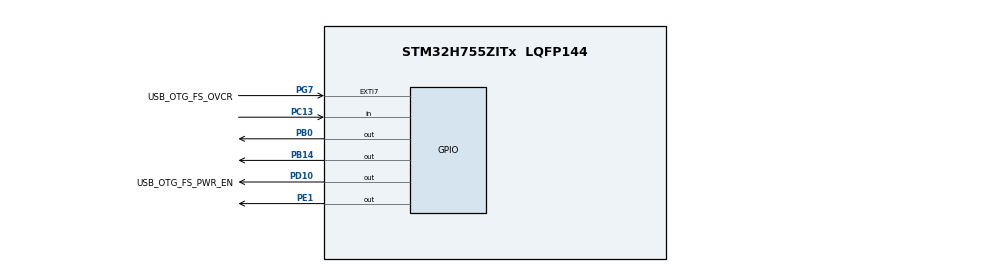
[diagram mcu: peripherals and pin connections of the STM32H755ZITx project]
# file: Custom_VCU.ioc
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CortexM4.IPs=FATFS_M4\:I,FREERTOS_M4\:I,IWDG2\:I,RCC,WWDG2\:I,DMA,BDMA,MDMA,NVIC2\:I,ETH,USART3,DEBUG,PDM2PCM_M4\:I,PWR,RESMGR_UTILITY,SYS_M4\:I,USB_DEVICE_M4\:I,USB_HOST_M4\:I,CORTEX_M4\:I,GPIO,OPENAMP_M4\:I,VREFBUF,NUCLEO-H755ZI-Q,TIM2\:I
CortexM7.IPs=FATFS_M7\:I,FREERTOS_M7\:I,IWDG1\:I,RCC\:I,WWDG1\:I,DMA\:I,BDMA\:I,MDMA\:I,NVIC1\:I,ETH\:I,USART3\:I,USB_OTG_FS\:I,SYS\:I,CORTEX_M7\:I,DEBUG\:I,PDM2PCM_M7\:I,PWR\:I,RESMGR_UTILITY\:I,USB_DEVICE_M7\:I,USB_HOST_M7\:I,GPIO\:I,OPENAMP_M7\:I,VREFBUF\:I,NUCLEO-H755ZI-Q\:I,MEMORYMAP\:I,TIM1\:I
FREERTOS_M4.Tasks01=defaultTask,0,128,StartDefaultTask,Default,NULL,Dynamic,NULL,NULL
FREERTOS_M4.configUSE_NEWLIB_REENTRANT=1
FREERTOS_M7.Tasks01=defaultTask,0,128,StartDefaultTask,Default,NULL,Dynamic,NULL,NULL
FREERTOS_M7.configUSE_NEWLIB_REENTRANT=1
Mcu.Family=STM32H7
Mcu.Name=STM32H755ZITx
Mcu.Package=LQFP144
NUCLEO-H755ZI-Q.BUTTON=1
NUCLEO-H755ZI-Q.Bsp_Common_DEMO=true
NUCLEO-H755ZI-Q.LD1=true
NUCLEO-H755ZI-Q.LD2=true
NUCLEO-H755ZI-Q.LD3=true
NUCLEO-H755ZI-Q.VCP=true
NVIC1.EXTI15_10_IRQn=true\:5\:0\:false\:false\:true\:true\:false\:true\:true
NVIC1.PriorityGroup=NVIC_PRIORITYGROUP_4
NVIC1.TIM1_UP_IRQn=true\:15\:0\:false\:false\:true\:false\:false\:true\:true
NVIC1.TimeBase=TIM1_UP_IRQn
NVIC1.TimeBaseIP=TIM1
NVIC2.PriorityGroup=NVIC_PRIORITYGROUP_4
NVIC2.TIM2_IRQn=true\:15\:0\:false\:false\:true\:false\:false\:true\:true
NVIC2.TimeBase=TIM2_IRQn
NVIC2.TimeBaseIP=TIM2
PA1.PinAttribute=CortexM7
PA1.Signal=ETH_REF_CLK
PA11.PinAttribute=CortexM7
PA11.Signal=USB_OTG_FS_DM
PA12.PinAttribute=CortexM7
PA12.Signal=USB_OTG_FS_DP
PA2.PinAttribute=CortexM7
PA2.Signal=ETH_MDIO
PA7.PinAttribute=CortexM7
PA7.Signal=ETH_CRS_DV
PA8.PinAttribute=CortexM7
PA8.Signal=USB_OTG_FS_SOF
PA9.PinAttribute=CortexM7
PA9.Signal=USB_OTG_FS_VBUS
PB0.Signal=GPIO_Output
PB13.PinAttribute=CortexM7
PB13.Signal=ETH_TXD1
PB14.Signal=GPIO_Output
PC1.PinAttribute=CortexM7
PC1.Signal=ETH_MDC
PC13.Signal=GPIO_Input
PC14-OSC32_IN\ (OSC32_IN).PinAttribute=Free
PC14-OSC32_IN\ (OSC32_IN).Signal=RCC_OSC32_IN
PC15-OSC32_OUT\ (OSC32_OUT).PinAttribute=Free
PC15-OSC32_OUT\ (OSC32_OUT).Signal=RCC_OSC32_OUT
PC4.PinAttribute=CortexM7
PC4.Signal=ETH_RXD0
PC5.PinAttribute=CortexM7
PC5.Signal=ETH_RXD1
PD10.GPIO_Label=USB_OTG_FS_PWR_EN
PD10.PinAttribute=Free
PD10.Signal=GPIO_Output
PD8.Signal=USART3_TX
PD9.Signal=USART3_RX
PE1.Signal=GPIO_Output
PG11.PinAttribute=CortexM7
PG11.Signal=ETH_TX_EN
PG13.PinAttribute=CortexM7
PG13.Signal=ETH_TXD0
PG7.GPIO_Label=USB_OTG_FS_OVCR
PG7.PinAttribute=Free
PG7.Signal=GPXTI7
PH0-OSC_IN\ (PH0).PinAttribute=Free
PH0-OSC_IN\ (PH0).Signal=RCC_OSC_IN
PH1-OSC_OUT\ (PH1).PinAttribute=Free
PH1-OSC_OUT\ (PH1).Signal=RCC_OSC_OUT
ProjectManager.HeapSize=M4-0x200,M7-0x200
ProjectManager.StackSize=M4-0x400,M7-0x400
ProjectManager.TargetToolchain=STM32CubeIDE
RCC.ADCFreq_Value=129000000
RCC.APB1Freq_Value=64000000
RCC.APB2Freq_Value=64000000
RCC.APB3Freq_Value=64000000
RCC.APB4Freq_Value=64000000
RCC.CortexFreq_Value=64000000
RCC.DIVM1=5
RCC.DIVN1=48
RCC.DIVQ1=5
RCC.HCLKFreq_Value=64000000
RCC.PLL2FRACN=0
RCC.PLL3FRACN=0
RCC.PLLFRACN=0
RCC.SYSCLKFreq_VALUE=64000000
RCC.SupplySource=PWR_DIRECT_SMPS_SUPPLY
RCC.USBFreq_Value=122880000
VP_FREERTOS_M4_VS_CMSIS_V1.Mode=CMSIS_V1
VP_FREERTOS_M7_VS_CMSIS_V1.Mode=CMSIS_V1
VP_MEMORYMAP_VS_MEMORYMAP.Mode=CurAppReg
VP_NUCLEO-H755ZI-Q_VS_BSP_COMMON.Mode=COMMON
VP_SYS_M4_VS_tim2.Mode=TIM2
VP_SYS_VS_tim1.Mode=TIM1
board=NUCLEO-H755ZI-Q

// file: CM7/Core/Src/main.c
/* USER CODE BEGIN Header */
/**
  ******************************************************************************
  * @file           : CM7 main.c
  * @brief          : Main program body
  ******************************************************************************
  * @attention
  *
  * Copyright (c) 2025 STMicroelectronics.
  * All rights reserved.
  *
  * This software is licensed under terms that can be found in the LICENSE file
  * in the root directory of this software component.
  * If no LICENSE file comes with this software, it is provided AS-IS.
  *
  ******************************************************************************
  */
/* USER CODE END Header */
#include "main.h"
#include "cmsis_os.h"

/* USER CODE BEGIN PD */

/* DUAL_CORE_BOOT_SYNC_SEQUENCE: Define for dual core boot synchronization    */
/*                             demonstration code based on hardware semaphore */
/* This define is present in both CM7/CM4 projects                            */
/* To comment when developping/debugging on a single core                     */
#define DUAL_CORE_BOOT_SYNC_SEQUENCE

#if defined(DUAL_CORE_BOOT_SYNC_SEQUENCE)
#ifndef HSEM_ID_0
#define HSEM_ID_0 (0U) /* HW semaphore 0*/
#endif
#endif /* DUAL_CORE_BOOT_SYNC_SEQUENCE */

/* USER CODE END PD */

COM_InitTypeDef BspCOMInit;
__IO uint32_t BspButtonState = BUTTON_RELEASED;

osThreadId defaultTaskHandle;

void SystemClock_Config(void);
static void MX_GPIO_Init(void);
void StartDefaultTask(void const * argument);

int main(void)
{

/* USER CODE BEGIN Boot_Mode_Sequence_0 */
#if defined(DUAL_CORE_BOOT_SYNC_SEQUENCE)
  int32_t timeout;
#endif /* DUAL_CORE_BOOT_SYNC_SEQUENCE */
/* USER CODE END Boot_Mode_Sequence_0 */

/* USER CODE BEGIN Boot_Mode_Sequence_1 */
#if defined(DUAL_CORE_BOOT_SYNC_SEQUENCE)
  /* Wait until CPU2 boots and enters in stop mode or timeout*/
  timeout = 0xFFFF;
  while((__HAL_RCC_GET_FLAG(RCC_FLAG_D2CKRDY) != RESET) && (timeout-- > 0));
  if ( timeout < 0 )
  {
  Error_Handler();
  }
#endif /* DUAL_CORE_BOOT_SYNC_SEQUENCE */
/* USER CODE END Boot_Mode_Sequence_1 */
  /* MCU Configuration--------------------------------------------------------*/

  /* Reset of all peripherals, Initializes the Flash interface and the Systick. */
  HAL_Init();

  /* Configure the system clock */
  SystemClock_Config();
/* USER CODE BEGIN Boot_Mode_Sequence_2 */
#if defined(DUAL_CORE_BOOT_SYNC_SEQUENCE)
/* When system initialization is finished, Cortex-M7 will release Cortex-M4 by means of
HSEM notification */
/*HW semaphore Clock enable*/
__HAL_RCC_HSEM_CLK_ENABLE();
/*Take HSEM */
HAL_HSEM_FastTake(HSEM_ID_0);
/*Release HSEM in order to notify the CPU2(CM4)*/
HAL_HSEM_Release(HSEM_ID_0,0);
/* wait until CPU2 wakes up from stop mode */
timeout = 0xFFFF;
while((__HAL_RCC_GET_FLAG(RCC_FLAG_D2CKRDY) == RESET) && (timeout-- > 0));
if ( timeout < 0 )
{
Error_Handler();
}
#endif /* DUAL_CORE_BOOT_SYNC_SEQUENCE */
/* USER CODE END Boot_Mode_Sequence_2 */

  /* Initialize all configured peripherals */
  MX_GPIO_Init();

  /* Create the thread(s) */
  /* definition and creation of defaultTask */
  osThreadDef(defaultTask, StartDefaultTask, osPriorityNormal, 0, 128);
  defaultTaskHandle = osThreadCreate(osThread(defaultTask), NULL);

  /* Initialize leds */
  BSP_LED_Init(LED_GREEN);
  BSP_LED_Init(LED_YELLOW);
  BSP_LED_Init(LED_RED);

  /* Initialize USER push-button, will be used to trigger an interrupt each time it's pressed.*/
  BSP_PB_Init(BUTTON_USER, BUTTON_MODE_EXTI);

  /* Initialize COM1 port (115200, 8 bits (7-bit data + 1 stop bit), no parity */
  BspCOMInit.BaudRate   = 115200;
  BspCOMInit.WordLength = COM_WORDLENGTH_8B;
  BspCOMInit.StopBits   = COM_STOPBITS_1;
  BspCOMInit.Parity     = COM_PARITY_NONE;
  BspCOMInit.HwFlowCtl  = COM_HWCONTROL_NONE;
  if (BSP_COM_Init(COM1, &BspCOMInit) != BSP_ERROR_NONE)
  {
    Error_Handler();
  }

  /* USER CODE BEGIN BSP */
  /* -- Sample board code to send message over COM1 port ---- */
  printf("Welcome to STM32 world !\n\r");
  /* -- Sample board code to switch on leds ---- */
  BSP_LED_On(LED_GREEN);
  BSP_LED_On(LED_YELLOW);
  BSP_LED_On(LED_RED);
  /* USER CODE END BSP */

  /* Start scheduler */
  osKernelStart();

  /* We should never get here as control is now taken by the scheduler */

  /* Infinite loop */
  /* USER CODE BEGIN WHILE */
  while (1)
  {

    /* -- Sample board code for User push-button in interrupt mode ---- */
    if (BspButtonState == BUTTON_PRESSED)
    {
      /* Update button state */
      BspButtonState = BUTTON_RELEASED;
      /* -- Sample board code to toggle leds ---- */
      BSP_LED_Toggle(LED_GREEN);
      BSP_LED_Toggle(LED_YELLOW);
      BSP_LED_Toggle(LED_RED);
      /* ..... Perform your action ..... */
    }
    /* USER CODE END WHILE */

  }
}

void SystemClock_Config(void)
{
  RCC_OscInitTypeDef RCC_OscInitStruct = {0};
  RCC_ClkInitTypeDef RCC_ClkInitStruct = {0};

  /** Supply configuration update enable
  */
  HAL_PWREx_ConfigSupply(PWR_DIRECT_SMPS_SUPPLY);

  /** Configure the main internal regulator output voltage
  */
  __HAL_PWR_VOLTAGESCALING_CONFIG(PWR_REGULATOR_VOLTAGE_SCALE3);

  while(!__HAL_PWR_GET_FLAG(PWR_FLAG_VOSRDY)) {}

  /** Initializes the RCC Oscillators according to the specified parameters
  * in the RCC_OscInitTypeDef structure.
  */
  RCC_OscInitStruct.OscillatorType = RCC_OSCILLATORTYPE_HSI;
  RCC_OscInitStruct.HSIState = RCC_HSI_DIV1;
  RCC_OscInitStruct.HSICalibrationValue = RCC_HSICALIBRATION_DEFAULT;
  RCC_OscInitStruct.PLL.PLLState = RCC_PLL_NONE;
  if (HAL_RCC_OscConfig(&RCC_OscInitStruct) != HAL_OK)
  {
    Error_Handler();
  }

  /** Initializes the CPU, AHB and APB buses clocks
  */
  RCC_ClkInitStruct.ClockType = RCC_CLOCKTYPE_HCLK|RCC_CLOCKTYPE_SYSCLK
                              |RCC_CLOCKTYPE_PCLK1|RCC_CLOCKTYPE_PCLK2
                              |RCC_CLOCKTYPE_D3PCLK1|RCC_CLOCKTYPE_D1PCLK1;
  RCC_ClkInitStruct.SYSCLKSource = RCC_SYSCLKSOURCE_HSI;
  RCC_ClkInitStruct.SYSCLKDivider = RCC_SYSCLK_DIV1;
  RCC_ClkInitStruct.AHBCLKDivider = RCC_HCLK_DIV1;
  RCC_ClkInitStruct.APB3CLKDivider = RCC_APB3_DIV1;
  RCC_ClkInitStruct.APB1CLKDivider = RCC_APB1_DIV1;
  RCC_ClkInitStruct.APB2CLKDivider = RCC_APB2_DIV1;
  RCC_ClkInitStruct.APB4CLKDivider = RCC_APB4_DIV1;

  if (HAL_RCC_ClockConfig(&RCC_ClkInitStruct, FLASH_LATENCY_1) != HAL_OK)
  {
    Error_Handler();
  }
}

static void MX_GPIO_Init(void)
{
  GPIO_InitTypeDef GPIO_InitStruct = {0};

  /* GPIO Ports Clock Enable */
  __HAL_RCC_GPIOC_CLK_ENABLE();
  __HAL_RCC_GPIOA_CLK_ENABLE();
  __HAL_RCC_GPIOB_CLK_ENABLE();
  __HAL_RCC_GPIOG_CLK_ENABLE();

  /*Configure GPIO pins : PC1 PC4 PC5 */
  GPIO_InitStruct.Pin = GPIO_PIN_1|GPIO_PIN_4|GPIO_PIN_5;
  GPIO_InitStruct.Mode = GPIO_MODE_AF_PP;
  GPIO_InitStruct.Pull = GPIO_NOPULL;
  GPIO_InitStruct.Speed = GPIO_SPEED_FREQ_LOW;
  GPIO_InitStruct.Alternate = GPIO_AF11_ETH;
  HAL_GPIO_Init(GPIOC, &GPIO_InitStruct);

  /*Configure GPIO pins : PA1 PA2 PA7 */
  GPIO_InitStruct.Pin = GPIO_PIN_1|GPIO_PIN_2|GPIO_PIN_7;
  GPIO_InitStruct.Mode = GPIO_MODE_AF_PP;
  GPIO_InitStruct.Pull = GPIO_NOPULL;
  GPIO_InitStruct.Speed = GPIO_SPEED_FREQ_LOW;
  GPIO_InitStruct.Alternate = GPIO_AF11_ETH;
  HAL_GPIO_Init(GPIOA, &GPIO_InitStruct);

  /*Configure GPIO pin : PB13 */
  GPIO_InitStruct.Pin = GPIO_PIN_13;
  GPIO_InitStruct.Mode = GPIO_MODE_AF_PP;
  GPIO_InitStruct.Pull = GPIO_NOPULL;
  GPIO_InitStruct.Speed = GPIO_SPEED_FREQ_LOW;
  GPIO_InitStruct.Alternate = GPIO_AF11_ETH;
  HAL_GPIO_Init(GPIOB, &GPIO_InitStruct);

  /*Configure GPIO pins : PA8 PA11 PA12 */
  GPIO_InitStruct.Pin = GPIO_PIN_8|GPIO_PIN_11|GPIO_PIN_12;
  GPIO_InitStruct.Mode = GPIO_MODE_AF_PP;
  GPIO_InitStruct.Pull = GPIO_NOPULL;
  GPIO_InitStruct.Speed = GPIO_SPEED_FREQ_LOW;
  GPIO_InitStruct.Alternate = GPIO_AF10_OTG1_FS;
  HAL_GPIO_Init(GPIOA, &GPIO_InitStruct);

  /*Configure GPIO pins : PG11 PG13 */
  GPIO_InitStruct.Pin = GPIO_PIN_11|GPIO_PIN_13;
  GPIO_InitStruct.Mode = GPIO_MODE_AF_PP;
  GPIO_InitStruct.Pull = GPIO_NOPULL;
  GPIO_InitStruct.Speed = GPIO_SPEED_FREQ_LOW;
  GPIO_InitStruct.Alternate = GPIO_AF11_ETH;
  HAL_GPIO_Init(GPIOG, &GPIO_InitStruct);

}

void StartDefaultTask(void const * argument)
{
  for(;;)
  {
    osDelay(1);
  }
}

void HAL_TIM_PeriodElapsedCallback(TIM_HandleTypeDef *htim)
{
  if (htim->Instance == TIM1)
  {
    HAL_IncTick();
  }
}

/**
  * @brief  BSP Push Button callback
  * @param  Button Specifies the pressed button
  * @retval None
  */
void BSP_PB_Callback(Button_TypeDef Button)
{
  if (Button == BUTTON_USER)
  {
    BspButtonState = BUTTON_PRESSED;
  }
}

void Error_Handler(void)
{
  __disable_irq();
  while (1)
  {
  }
}
